AUTOSAR XML (schema 4-2-2)
# \copyright BMW AG 2015 - 2017
package /BMW/Platform/Vin/SwComponentTypes
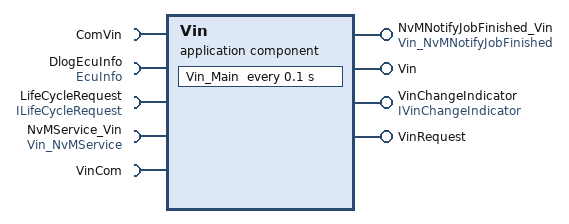
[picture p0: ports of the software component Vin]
  application sw component type Vin
    require port ComVin: nonqueued-receiver-com-spec{data-element=ComVin, uses-end-to-end-protection=0, init-value=fields=[Vin1:0, Vin2:0, Vin3:0, Vin4:0, Vin5:0, Vin6:0, Vin7:0]}, required-interface=ComVin
    require port DlogEcuInfo: required-interface=EcuInfo
    provide/require port LifeCycle: mode-switch-sender-com-spec{enhanced-mode-api=true, mode-group=Mode, queue-length=2}, provided-required-interface=ILifeCycle
    require port LifeCycleRequest: nonqueued-receiver-com-spec{data-element=requestMode, init-value=2}, required-interface=ILifeCycleRequest
    provide port NvMNotifyJobFinished_Vin: provided-interface=Vin_NvMNotifyJobFinished
    require port NvMService_Vin: required-interface=Vin_NvMService
    provide port Vin: nonqueued-sender-com-spec{data-element=Vin, uses-end-to-end-protection=0, init-value={short-label=InitValue_Vin, fields=[Vin:7 x 0, Qualifier:0]}}, provided-interface=Vin
    provide port VinChangeIndicator: mode-switch-sender-com-spec{mode-group=ChangeIndicator, mode-switched-ack=timeout=0.0, queue-length=1}, provided-interface=IVinChangeIndicator
    require port VinCom: required-interface=VinCom
    provide port VinRequest: queued-sender-com-spec{data-element=RequestMessageIdentifier, uses-end-to-end-protection=0}, provided-interface=VinRequest
    behavior Vin_IB: data-type-mapping=dtms_VinLifeCycleMode, handle-termination-and-restart=NO-SUPPORT
      exclusive area VinState
      data received event LifeCycleRequest: start-on-event=Vin_LifeCycleModeRequest, data=LifeCycleRequest.requestMode
      timing event Main: disabled-mode=[VinCom.Mode.VIN_VINCOMOFF, LifeCycle.Mode.VIN_INITIALIZED, LifeCycle.Mode.VIN_STOPPED], start-on-event=Vin_Main, period=0.1
      data received event dre_ComVin: start-on-event=Vin_ReceiveFromCom, data=ComVin.ComVin
      mode switched ack event msae_VinChangeIndicator: start-on-event=Vin_OnVinChangeIndicatorAck, event-source=mspVinChangeIndicator
      swc mode switch event mse_ComOff: start-on-event=Vin_OnComOff, activation=ON-TRANSITION, mode=[VinCom.Mode.VIN_VINCOMON, VinCom.Mode.VIN_VINCOMOFF]
      swc mode switch event mse_ComOn: start-on-event=Vin_OnComOn, activation=ON-TRANSITION, mode=[VinCom.Mode.VIN_VINCOMOFF, VinCom.Mode.VIN_VINCOMON]
      operation invoked event oie_NvMNotifyJobFinished_Vin_JobFinished: start-on-event=Vin_NvmJobFinished, operation=NvMNotifyJobFinished_Vin.JobFinished
      7 x runnable:
        Vin_LifeCycleModeRequest: runs-inside-exclusive-area=VinState, mode-access-point=LifeCycle.Mode
          data-read-access:
            access dra_requestMode: accessed-variable=LifeCycleRequest.requestMode
          mode switch point msp_LifeCycle: mode-group=LifeCycle.Mode
        Vin_Main: can-enter-exclusive-area=VinState
          data-send-points:
            access dsp_RequestMessageIdentifier: accessed-variable=VinRequest.RequestMessageIdentifier
          sync call scp_GetErrorStatus: operation=NvMService_Vin.GetErrorStatus, timeout=0.0
          sync call scp_ReadBlock: operation=NvMService_Vin.ReadBlock, timeout=0.0
        Vin_NvmJobFinished: can-enter-exclusive-area=VinState
          mode switch point msp_VinChangeIndicator: mode-group=VinChangeIndicator.ChangeIndicator
          sync call scp_WriteBlock: operation=NvMService_Vin.WriteBlock, timeout=0.0
        Vin_OnComOff
        Vin_OnComOn: runs-inside-exclusive-area=VinState
        Vin_OnVinChangeIndicatorAck: runs-inside-exclusive-area=VinState, mode-access-point=VinChangeIndicator.ChangeIndicator
          mode switch point mspVinChangeIndicator: mode-group=VinChangeIndicator.ChangeIndicator
          sync call scp_WriteBlock: operation=NvMService_Vin.WriteBlock, timeout=0.0
        Vin_ReceiveFromCom: can-enter-exclusive-area=VinState
          data-read-access:
            access dra_ComVin: accessed-variable=ComVin.ComVin
          data-send-points:
            access dsp_Vin: accessed-variable=Vin.Vin
          mode switch point msp_VinChangeIndicator: mode-group=VinChangeIndicator.ChangeIndicator
          sync call scp_GetVin: operation=DlogEcuInfo.GetVin, timeout=0.0
          sync call scp_WriteBlock: operation=NvMService_Vin.WriteBlock, timeout=0.0
  swc implementation Vin_Impl: programming-language=C, sw-version=3.5.0, vendor-id=5, behavior=Vin_IB
    code-descriptors:
      code Vin_Impl_Code: artifact-descriptors=autosar-engineering-object={short-label=Vin_Impl_Code_CodeDesc, category=SWSRC}
    resource consumption Vin_Impl_ResCons
